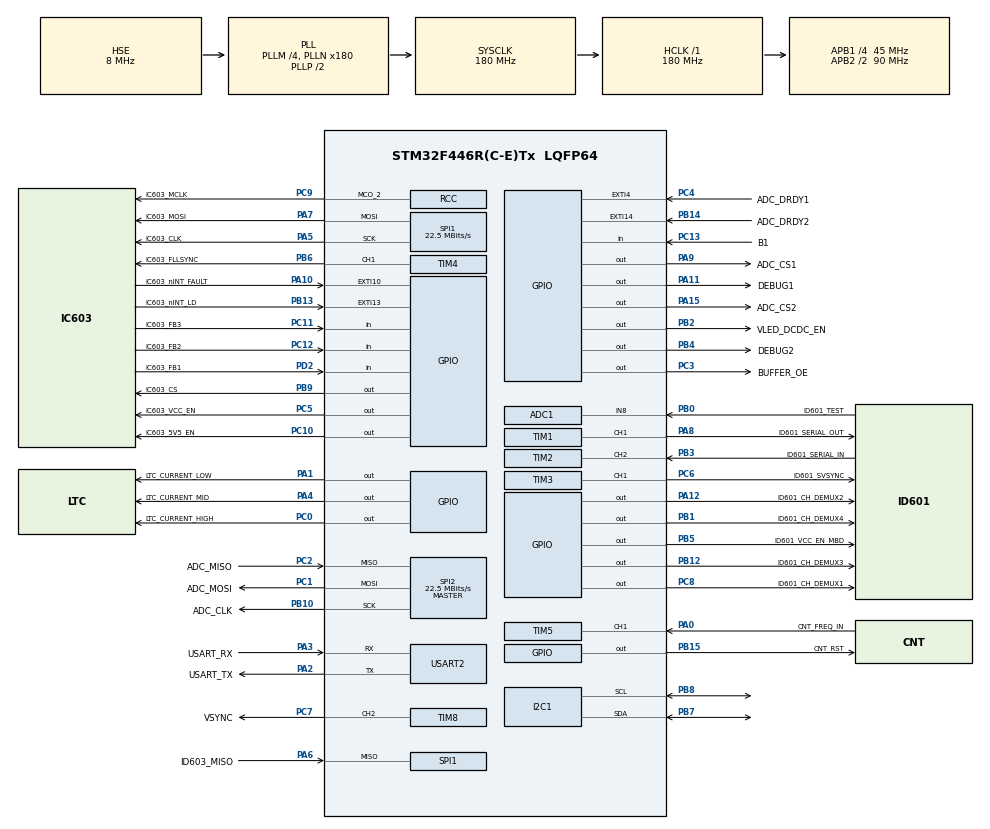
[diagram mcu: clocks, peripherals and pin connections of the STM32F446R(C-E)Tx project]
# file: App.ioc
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ADC1.Channel-0\#ChannelRegularConversion=ADC_CHANNEL_8
ADC1.ContinuousConvMode=ENABLE
ADC1.NbrOfConversionFlag=1
ADC1.Rank-0\#ChannelRegularConversion=1
ADC1.SamplingTime-0\#ChannelRegularConversion=ADC_SAMPLETIME_480CYCLES
ADC1.master=1
Dma.Request0=TIM1_CH1
Dma.Request1=TIM2_CH2/CH4
Dma.Request2=TIM5_CH1
Dma.Request3=SPI1_TX
Dma.Request4=SPI2_TX
Dma.Request5=SPI1_RX
Dma.Request6=SPI2_RX
Dma.SPI1_RX.5.Direction=DMA_PERIPH_TO_MEMORY
Dma.SPI1_RX.5.FIFOMode=DMA_FIFOMODE_DISABLE
Dma.SPI1_RX.5.Instance=DMA2_Stream0
Dma.SPI1_RX.5.MemDataAlignment=DMA_MDATAALIGN_HALFWORD
Dma.SPI1_RX.5.MemInc=DMA_MINC_ENABLE
Dma.SPI1_RX.5.Mode=DMA_NORMAL
Dma.SPI1_RX.5.PeriphDataAlignment=DMA_PDATAALIGN_HALFWORD
Dma.SPI1_RX.5.PeriphInc=DMA_PINC_DISABLE
Dma.SPI1_RX.5.Priority=DMA_PRIORITY_LOW
Dma.SPI1_TX.3.Direction=DMA_MEMORY_TO_PERIPH
Dma.SPI1_TX.3.FIFOMode=DMA_FIFOMODE_DISABLE
Dma.SPI1_TX.3.Instance=DMA2_Stream3
Dma.SPI1_TX.3.MemDataAlignment=DMA_MDATAALIGN_HALFWORD
Dma.SPI1_TX.3.MemInc=DMA_MINC_ENABLE
Dma.SPI1_TX.3.Mode=DMA_NORMAL
Dma.SPI1_TX.3.PeriphDataAlignment=DMA_PDATAALIGN_HALFWORD
Dma.SPI1_TX.3.PeriphInc=DMA_PINC_DISABLE
Dma.SPI1_TX.3.Priority=DMA_PRIORITY_LOW
Dma.SPI2_RX.6.Direction=DMA_PERIPH_TO_MEMORY
Dma.SPI2_RX.6.FIFOMode=DMA_FIFOMODE_DISABLE
Dma.SPI2_RX.6.Instance=DMA1_Stream3
Dma.SPI2_RX.6.MemDataAlignment=DMA_MDATAALIGN_BYTE
Dma.SPI2_RX.6.MemInc=DMA_MINC_ENABLE
Dma.SPI2_RX.6.Mode=DMA_NORMAL
Dma.SPI2_RX.6.PeriphDataAlignment=DMA_PDATAALIGN_BYTE
Dma.SPI2_RX.6.PeriphInc=DMA_PINC_DISABLE
Dma.SPI2_RX.6.Priority=DMA_PRIORITY_LOW
Dma.SPI2_TX.4.Direction=DMA_MEMORY_TO_PERIPH
Dma.SPI2_TX.4.FIFOMode=DMA_FIFOMODE_DISABLE
Dma.SPI2_TX.4.Instance=DMA1_Stream4
Dma.SPI2_TX.4.MemDataAlignment=DMA_MDATAALIGN_BYTE
Dma.SPI2_TX.4.MemInc=DMA_MINC_ENABLE
Dma.SPI2_TX.4.Mode=DMA_NORMAL
Dma.SPI2_TX.4.PeriphDataAlignment=DMA_PDATAALIGN_BYTE
Dma.SPI2_TX.4.PeriphInc=DMA_PINC_DISABLE
Dma.SPI2_TX.4.Priority=DMA_PRIORITY_LOW
Dma.TIM1_CH1.0.Direction=DMA_MEMORY_TO_PERIPH
Dma.TIM1_CH1.0.FIFOMode=DMA_FIFOMODE_DISABLE
Dma.TIM1_CH1.0.Instance=DMA2_Stream1
Dma.TIM1_CH1.0.MemDataAlignment=DMA_MDATAALIGN_HALFWORD
Dma.TIM1_CH1.0.MemInc=DMA_MINC_ENABLE
Dma.TIM1_CH1.0.Mode=DMA_NORMAL
Dma.TIM1_CH1.0.PeriphDataAlignment=DMA_PDATAALIGN_HALFWORD
Dma.TIM1_CH1.0.PeriphInc=DMA_PINC_DISABLE
Dma.TIM1_CH1.0.Priority=DMA_PRIORITY_LOW
Dma.TIM2_CH2/CH4.1.Direction=DMA_PERIPH_TO_MEMORY
Dma.TIM2_CH2/CH4.1.FIFOMode=DMA_FIFOMODE_DISABLE
Dma.TIM2_CH2/CH4.1.Instance=DMA1_Stream6
Dma.TIM2_CH2/CH4.1.MemDataAlignment=DMA_MDATAALIGN_HALFWORD
Dma.TIM2_CH2/CH4.1.MemInc=DMA_MINC_ENABLE
Dma.TIM2_CH2/CH4.1.Mode=DMA_NORMAL
Dma.TIM2_CH2/CH4.1.PeriphDataAlignment=DMA_PDATAALIGN_HALFWORD
Dma.TIM2_CH2/CH4.1.PeriphInc=DMA_PINC_DISABLE
Dma.TIM2_CH2/CH4.1.Priority=DMA_PRIORITY_LOW
Dma.TIM5_CH1.2.Direction=DMA_PERIPH_TO_MEMORY
Dma.TIM5_CH1.2.FIFOMode=DMA_FIFOMODE_DISABLE
Dma.TIM5_CH1.2.Instance=DMA1_Stream2
Dma.TIM5_CH1.2.MemDataAlignment=DMA_MDATAALIGN_WORD
Dma.TIM5_CH1.2.MemInc=DMA_MINC_ENABLE
Dma.TIM5_CH1.2.Mode=DMA_NORMAL
Dma.TIM5_CH1.2.PeriphDataAlignment=DMA_PDATAALIGN_WORD
Dma.TIM5_CH1.2.PeriphInc=DMA_PINC_DISABLE
Dma.TIM5_CH1.2.Priority=DMA_PRIORITY_LOW
FREERTOS.Tasks01=ID601TestTask,24,1024,StartID601TestTask,Default,NULL,Dynamic,NULL,NULL;CLITask,8,1024,StartCLITask,Default,NULL,Dynamic,NULL,NULL;ID601TrimTask,8,1024,StartID601TrimTask,Default,NULL,Dynamic,NULL,NULL;VsyncTask,8,256,StartVsyncTask,Default,NULL,Dynamic,NULL,NULL;BTNTask,8,128,StartBTNTask,Default,NULL,Dynamic,NULL,NULL
Mcu.Family=STM32F4
Mcu.Name=STM32F446R(C-E)Tx
Mcu.Package=LQFP64
NVIC.ADC_IRQn=true\:5\:0\:false\:false\:true\:true\:true\:true\:true
NVIC.DMA1_Stream2_IRQn=true\:5\:0\:false\:false\:true\:true\:false\:true\:true
NVIC.DMA1_Stream3_IRQn=true\:5\:0\:false\:false\:true\:true\:false\:true\:true
NVIC.DMA1_Stream4_IRQn=true\:5\:0\:false\:false\:true\:true\:false\:true\:true
NVIC.DMA1_Stream6_IRQn=true\:5\:0\:false\:false\:true\:true\:false\:true\:true
NVIC.DMA2_Stream0_IRQn=true\:5\:0\:false\:false\:true\:true\:false\:true\:true
NVIC.DMA2_Stream1_IRQn=true\:5\:0\:false\:false\:true\:true\:false\:true\:true
NVIC.DMA2_Stream3_IRQn=true\:5\:0\:false\:false\:true\:true\:false\:true\:true
NVIC.EXTI15_10_IRQn=true\:5\:0\:false\:false\:true\:true\:true\:true\:true
NVIC.EXTI4_IRQn=true\:5\:0\:false\:false\:true\:true\:true\:true\:true
NVIC.PriorityGroup=NVIC_PRIORITYGROUP_4
NVIC.TIM1_TRG_COM_TIM11_IRQn=true\:6\:0\:true\:false\:true\:true\:true\:true\:true
NVIC.TIM3_IRQn=true\:5\:0\:false\:false\:true\:true\:true\:true\:true
NVIC.TIM8_BRK_TIM12_IRQn=true\:5\:0\:false\:false\:true\:true\:true\:true\:true
NVIC.TIM8_TRG_COM_TIM14_IRQn=true\:4\:0\:true\:false\:true\:false\:false\:true\:true
NVIC.TIM8_UP_TIM13_IRQn=true\:6\:0\:true\:false\:true\:true\:true\:true\:true
NVIC.TimeBase=TIM8_TRG_COM_TIM14_IRQn
NVIC.TimeBaseIP=TIM14
NVIC.USART2_IRQn=true\:5\:0\:false\:false\:true\:true\:true\:true\:true
PA0-WKUP.GPIO_Label=CNT_FREQ_IN
PA0-WKUP.GPIO_Speed=GPIO_SPEED_FREQ_VERY_HIGH
PA0-WKUP.Signal=S_TIM5_CH1
PA1.GPIO_Label=LTC_CURRENT_LOW
PA1.Signal=GPIO_Output
PA10.GPIO_Label=IC603_nINT_FAULT
PA10.GPIO_ModeDefaultEXTI=GPIO_MODE_IT_FALLING
PA10.GPIO_PuPd=GPIO_NOPULL
PA10.Signal=GPXTI10
PA11.GPIO_Label=DEBUG1
PA11.Signal=GPIO_Output
PA12.GPIO_Label=ID601_CH_DEMUX2
PA12.PinState=GPIO_PIN_SET
PA12.Signal=GPIO_Output
PA13.GPIO_Label=TMS
PA13.Mode=Serial_Wire
PA13.Signal=SYS_JTMS-SWDIO
PA14.GPIO_Label=TCK
PA14.Mode=Serial_Wire
PA14.Signal=SYS_JTCK-SWCLK
PA15.GPIO_Label=ADC_CS2
PA15.GPIO_Speed=GPIO_SPEED_FREQ_LOW
PA15.PinState=GPIO_PIN_SET
PA15.Signal=GPIO_Output
PA2.GPIO_Label=USART_TX
PA2.Mode=Asynchronous
PA2.Signal=USART2_TX
PA3.GPIO_Label=USART_RX
PA3.Mode=Asynchronous
PA3.Signal=USART2_RX
PA4.GPIO_Label=LTC_CURRENT_MID
PA4.Signal=GPIO_Output
PA5.GPIO_Label=IC603_CLK
PA5.Mode=Full_Duplex_Master
PA5.Signal=SPI1_SCK
PA6.GPIO_Label=ID603_MISO
PA6.Mode=Full_Duplex_Master
PA6.Signal=SPI1_MISO
PA7.GPIO_Label=IC603_MOSI
PA7.Mode=Full_Duplex_Master
PA7.Signal=SPI1_MOSI
PA8.GPIO_Label=ID601_SERIAL_OUT
PA8.GPIO_Speed=GPIO_SPEED_FREQ_HIGH
PA8.Signal=S_TIM1_CH1
PA9.GPIO_Label=ADC_CS1
PA9.GPIO_Speed=GPIO_SPEED_FREQ_LOW
PA9.PinState=GPIO_PIN_SET
PA9.Signal=GPIO_Output
PB0.GPIO_Label=ID601_TEST
PB0.Signal=ADCx_IN8
PB1.GPIO_Label=ID601_CH_DEMUX4
PB1.PinState=GPIO_PIN_SET
PB1.Signal=GPIO_Output
PB10.GPIO_Label=ADC_CLK
PB10.Mode=Full_Duplex_Master
PB10.Signal=SPI2_SCK
PB12.GPIO_Label=ID601_CH_DEMUX3
PB12.PinState=GPIO_PIN_SET
PB12.Signal=GPIO_Output
PB13.GPIO_Label=IC603_nINT_LD
PB13.GPIO_ModeDefaultEXTI=GPIO_MODE_IT_FALLING
PB13.GPIO_PuPd=GPIO_NOPULL
PB13.Signal=GPXTI13
PB14.GPIO_Label=ADC_DRDY2
PB14.GPIO_ModeDefaultEXTI=GPIO_MODE_IT_FALLING
PB14.GPIO_PuPd=GPIO_PULLUP
PB14.Signal=GPXTI14
PB15.GPIO_Label=CNT_RST
PB15.GPIO_Speed=GPIO_SPEED_FREQ_LOW
PB15.PinState=GPIO_PIN_SET
PB15.Signal=GPIO_Output
PB2.GPIO_Label=VLED_DCDC_EN
PB2.PinState=GPIO_PIN_SET
PB2.Signal=GPIO_Output
PB3.GPIO_Label=ID601_SERIAL_IN
PB3.GPIO_Speed=GPIO_SPEED_FREQ_VERY_HIGH
PB3.Signal=S_TIM2_CH2
PB4.GPIO_Label=DEBUG2
PB4.Signal=GPIO_Output
PB5.GPIO_Label=ID601_VCC_EN_MBD
PB5.PinState=GPIO_PIN_SET
PB5.Signal=GPIO_Output
PB6.GPIO_Label=IC603_FLLSYNC
PB6.GPIO_Speed=GPIO_SPEED_FREQ_HIGH
PB6.Signal=S_TIM4_CH1
PB7.Mode=I2C
PB7.Signal=I2C1_SDA
PB8.Mode=I2C
PB8.Signal=I2C1_SCL
PB9.GPIO_Label=IC603_CS
PB9.PinState=GPIO_PIN_SET
PB9.Signal=GPIO_Output
PC0.GPIO_Label=LTC_CURRENT_HIGH
PC0.Signal=GPIO_Output
PC1.GPIO_Label=ADC_MOSI
PC1.Mode=Full_Duplex_Master
PC1.Signal=SPI2_MOSI
PC10.GPIO_Label=IC603_5V5_EN
PC10.Signal=GPIO_Output
PC11.GPIO_Label=IC603_FB3
PC11.Signal=GPIO_Input
PC12.GPIO_Label=IC603_FB2
PC12.Signal=GPIO_Input
PC13.GPIO_Label=B1
PC13.Signal=GPIO_Input
PC14-OSC32_IN.Mode=LSE-External-Oscillator
PC14-OSC32_IN.Signal=RCC_OSC32_IN
PC15-OSC32_OUT.Mode=LSE-External-Oscillator
PC15-OSC32_OUT.Signal=RCC_OSC32_OUT
PC2.GPIO_Label=ADC_MISO
PC2.Mode=Full_Duplex_Master
PC2.Signal=SPI2_MISO
PC3.GPIO_Label=BUFFER_OE
PC3.GPIO_Speed=GPIO_SPEED_FREQ_LOW
PC3.Signal=GPIO_Output
PC4.GPIO_Label=ADC_DRDY1
PC4.GPIO_ModeDefaultEXTI=GPIO_MODE_IT_FALLING
PC4.GPIO_PuPd=GPIO_PULLUP
PC4.Signal=GPXTI4
PC5.GPIO_Label=IC603_VCC_EN
PC5.PinState=GPIO_PIN_SET
PC5.Signal=GPIO_Output
PC6.GPIO_Label=ID601_SVSYNC
PC6.GPIO_Speed=GPIO_SPEED_FREQ_HIGH
PC6.Signal=S_TIM3_CH1
PC7.GPIO_Label=VSYNC
PC7.Signal=S_TIM8_CH2
PC8.GPIO_Label=ID601_CH_DEMUX1
PC8.PinState=GPIO_PIN_SET
PC8.Signal=GPIO_Output
PC9.GPIO_Label=IC603_MCLK
PC9.Mode=Clock-out-2
PC9.Signal=RCC_MCO_2
PD2.GPIO_Label=IC603_FB1
PD2.Signal=GPIO_Input
PH0-OSC_IN.Mode=HSE-External-Oscillator
PH0-OSC_IN.Signal=RCC_OSC_IN
PH1-OSC_OUT.Mode=HSE-External-Oscillator
PH1-OSC_OUT.Signal=RCC_OSC_OUT
ProjectManager.HeapSize=0x200
ProjectManager.StackSize=0x400
ProjectManager.TargetToolchain=EWARM V8.50
RCC.AHBFreq_Value=180000000
RCC.APB1CLKDivider=RCC_HCLK_DIV4
RCC.APB1Freq_Value=45000000
RCC.APB1TimFreq_Value=90000000
RCC.APB2CLKDivider=RCC_HCLK_DIV2
RCC.APB2Freq_Value=90000000
RCC.APB2TimFreq_Value=180000000
RCC.CortexFreq_Value=180000000
RCC.FLatency-AdvancedSettings=FLASH_LATENCY_5
RCC.HCLKFreq_Value=180000000
RCC.HSE_VALUE=8000000
RCC.HSI_VALUE=16000000
RCC.PLLM=4
RCC.PLLN=180
RCC.PLLSourceVirtual=RCC_PLLSOURCE_HSE
RCC.RCC_MCODiv2=RCC_MCODIV_2
RCC.SYSCLKFreq_VALUE=180000000
RCC.SYSCLKSource=RCC_SYSCLKSOURCE_PLLCLK
RCC.USBFreq_Value=180000000
RCC.VCOOutputFreq_Value=360000000
SH.ADCx_IN8.0=ADC1_IN8,IN8
SH.S_TIM1_CH1.0=TIM1_CH1,PWM Generation1 CH1
SH.S_TIM2_CH2.0=TIM2_CH2,PWM_Input_2
SH.S_TIM3_CH1.0=TIM3_CH1,PWM Generation1 CH1
SH.S_TIM4_CH1.0=TIM4_CH1,PWM Generation1 CH1
SH.S_TIM5_CH1.0=TIM5_CH1,Input_Capture1_from_TI1
SH.S_TIM8_CH2.0=TIM8_CH2,PWM Generation2 CH2
SPI1.BaudRatePrescaler=SPI_BAUDRATEPRESCALER_4
SPI1.CLKPhase=SPI_PHASE_2EDGE
SPI1.CalculateBaudRate=22.5 MBits/s
SPI1.DataSize=SPI_DATASIZE_16BIT
SPI1.Direction=SPI_DIRECTION_2LINES
SPI1.Mode=SPI_MODE_MASTER
SPI1.VirtualType=VM_MASTER
SPI2.CLKPhase=SPI_PHASE_2EDGE
SPI2.CalculateBaudRate=22.5 MBits/s
SPI2.Direction=SPI_DIRECTION_2LINES
SPI2.Mode=SPI_MODE_MASTER
SPI2.VirtualType=VM_MASTER
TIM1.AutomaticOutput=TIM_AUTOMATICOUTPUT_ENABLE
TIM1.Channel-PWM\ Generation1\ CH1=TIM_CHANNEL_1
TIM1.Period=179
TIM11.Period=59999
TIM11.Prescaler=24
TIM13.Prescaler=89
TIM2.ICPolarity_1=TIM_INPUTCHANNELPOLARITY_FALLING
TIM3.Channel-PWM\ Generation1\ CH1=TIM_CHANNEL_1
TIM3.OC1Preload_PWM=DISABLE
TIM3.Prescaler=1
TIM4.Channel-PWM\ Generation1\ CH1=TIM_CHANNEL_1
TIM4.Period=49999
TIM4.Prescaler=8
TIM5.Channel-Input_Capture1_from_TI1=TIM_CHANNEL_1
TIM8.AutoReloadPreload=TIM_AUTORELOAD_PRELOAD_ENABLE
TIM8.AutomaticOutput=TIM_AUTOMATICOUTPUT_ENABLE
TIM8.Channel-PWM\ Generation2\ CH2=TIM_CHANNEL_2
TIM8.Period=59999
TIM8.Prescaler=49
TIM8.TIM_MasterSlaveMode=TIM_MASTERSLAVEMODE_ENABLE
USART2.VirtualMode=VM_ASYNC
VP_FREERTOS_VS_CMSIS_V2.Mode=CMSIS_V2
VP_SYS_VS_tim14.Mode=TIM14
VP_TIM11_VS_ClockSourceINT.Mode=Enable_Timer
VP_TIM13_VS_ClockSourceINT.Mode=Enable_Timer
VP_TIM1_VS_ClockSourceINT.Mode=Internal
VP_TIM2_VS_ClockSourceINT.Mode=Internal
VP_TIM3_VS_ClockSourceINT.Mode=Internal
VP_TIM4_VS_ClockSourceINT.Mode=Internal
VP_TIM5_VS_ClockSourceINT.Mode=Internal
VP_TIM8_VS_ClockSourceINT.Mode=Internal
board=NUCLEO-F446RE

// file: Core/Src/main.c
/* USER CODE BEGIN Header */
/**
  ******************************************************************************
  * @file           : main.c
  * @brief          : Main program body
  ******************************************************************************
  * @attention
  *
  * Copyright (c) 2026 STMicroelectronics.
  * All rights reserved.
  *
  * This software is licensed under terms that can be found in the LICENSE file
  * in the root directory of this software component.
  * If no LICENSE file comes with this software, it is provided AS-IS.
  *
  ******************************************************************************
  */
/* USER CODE END Header */
#include "main.h"
#include "cmsis_os.h"

/* USER CODE BEGIN Includes */
#include "cli.h"
#include "drv_gpio.h"
#include "drv_uart.h"
#include "drv_timer.h"
#include "drv_id601.h"
#include "id601_trim.h"
#include "id601_test.h"
#include "id601_dimming.h"
#include "drv_ads114s08.h"
#include "common_def.h"
/* USER CODE END Includes */

I2C_HandleTypeDef hi2c1;

/* Definitions for ID601TestTask */
osThreadId_t ID601TestTaskHandle;
const osThreadAttr_t ID601TestTask_attributes = {
  .name = "ID601TestTask",
  .stack_size = 1024 * 4,
  .priority = (osPriority_t) osPriorityNormal,
};
/* Definitions for CLITask */
osThreadId_t CLITaskHandle;
const osThreadAttr_t CLITask_attributes = {
  .name = "CLITask",
  .stack_size = 1024 * 4,
  .priority = (osPriority_t) osPriorityLow,
};
/* Definitions for ID601TrimTask */
osThreadId_t ID601TrimTaskHandle;
const osThreadAttr_t ID601TrimTask_attributes = {
  .name = "ID601TrimTask",
  .stack_size = 1024 * 4,
  .priority = (osPriority_t) osPriorityLow,
};
/* Definitions for VsyncTask */
osThreadId_t VsyncTaskHandle;
const osThreadAttr_t VsyncTask_attributes = {
  .name = "VsyncTask",
  .stack_size = 256 * 4,
  .priority = (osPriority_t) osPriorityLow,
};
/* Definitions for BTNTask */
osThreadId_t BTNTaskHandle;
const osThreadAttr_t BTNTask_attributes = {
  .name = "BTNTask",
  .stack_size = 128 * 4,
  .priority = (osPriority_t) osPriorityLow,
};

void SystemClock_Config(void);
static void MX_GPIO_Init(void);
static void MX_DMA_Init(void);
static void MX_SPI1_Init(void);
static void MX_USART2_UART_Init(void);
static void MX_ADC1_Init(void);
static void MX_SPI2_Init(void);
static void MX_TIM1_Init(void);
static void MX_TIM2_Init(void);
static void MX_TIM3_Init(void);
static void MX_TIM4_Init(void);
static void MX_TIM5_Init(void);
static void MX_TIM8_Init(void);
static void MX_TIM13_Init(void);
static void MX_I2C1_Init(void);
static void MX_TIM11_Init(void);
void StartID601TestTask(void *argument);
void StartCLITask(void *argument);
void StartID601TrimTask(void *argument);
void StartVsyncTask(void *argument);
void StartBTNTask(void *argument);

int main(void)
{

  /* USER CODE BEGIN 1 */
  __enable_irq();
  /* USER CODE END 1 */

  /* MCU Configuration--------------------------------------------------------*/

  /* Reset of all peripherals, Initializes the Flash interface and the Systick. */
  HAL_Init();

  /* Configure the system clock */
  SystemClock_Config();

  /* Initialize all configured peripherals */
  MX_GPIO_Init();
  MX_DMA_Init();
  MX_SPI1_Init();
  MX_USART2_UART_Init();
  MX_ADC1_Init();
  MX_SPI2_Init();
  MX_TIM1_Init();
  MX_TIM2_Init();
  MX_TIM3_Init();
  MX_TIM4_Init();
  MX_TIM5_Init();
  MX_TIM8_Init();
  MX_TIM13_Init();
  MX_I2C1_Init();
  MX_TIM11_Init();
  /* USER CODE BEGIN 2 */
    drv_uart_init();

    drv_tim_init();
    drv_gpio_init();
    drv_id601_init();
    ads114s08_init();

    cli_init();
  /* USER CODE END 2 */

  /* Init scheduler */
  osKernelInitialize();

  /* USER CODE BEGIN RTOS_MUTEX */
  /* add mutexes, ... */
    drv_id601_make_mutex();
    drv_uart_make_mutex();
  /* USER CODE END RTOS_MUTEX */

  /* Create the thread(s) */
  /* creation of ID601TestTask */
  ID601TestTaskHandle = osThreadNew(StartID601TestTask, NULL, &ID601TestTask_attributes);

  /* creation of CLITask */
  CLITaskHandle = osThreadNew(StartCLITask, NULL, &CLITask_attributes);

  /* creation of ID601TrimTask */
  ID601TrimTaskHandle = osThreadNew(StartID601TrimTask, NULL, &ID601TrimTask_attributes);

  /* creation of VsyncTask */
  VsyncTaskHandle = osThreadNew(StartVsyncTask, NULL, &VsyncTask_attributes);

  /* creation of BTNTask */
  BTNTaskHandle = osThreadNew(StartBTNTask, NULL, &BTNTask_attributes);

  /* Start scheduler */
  osKernelStart();

  /* We should never get here as control is now taken by the scheduler */

  /* Infinite loop */
  while (1)
  {

  }
}

void SystemClock_Config(void)
{
  RCC_OscInitTypeDef RCC_OscInitStruct = {0};
  RCC_ClkInitTypeDef RCC_ClkInitStruct = {0};

  /** Configure the main internal regulator output voltage
  */
  __HAL_RCC_PWR_CLK_ENABLE();
  __HAL_PWR_VOLTAGESCALING_CONFIG(PWR_REGULATOR_VOLTAGE_SCALE1);

  /** Initializes the RCC Oscillators according to the specified parameters
  * in the RCC_OscInitTypeDef structure.
  */
  RCC_OscInitStruct.OscillatorType = RCC_OSCILLATORTYPE_HSE;
  RCC_OscInitStruct.HSEState = RCC_HSE_ON;
  RCC_OscInitStruct.PLL.PLLState = RCC_PLL_ON;
  RCC_OscInitStruct.PLL.PLLSource = RCC_PLLSOURCE_HSE;
  RCC_OscInitStruct.PLL.PLLM = 4;
  RCC_OscInitStruct.PLL.PLLN = 180;
  RCC_OscInitStruct.PLL.PLLP = RCC_PLLP_DIV2;
  RCC_OscInitStruct.PLL.PLLQ = 2;
  RCC_OscInitStruct.PLL.PLLR = 2;
  if (HAL_RCC_OscConfig(&RCC_OscInitStruct) != HAL_OK)
  {
    Error_Handler();
  }

  /** Activate the Over-Drive mode
  */
  if (HAL_PWREx_EnableOverDrive() != HAL_OK)
  {
    Error_Handler();
  }

  /** Initializes the CPU, AHB and APB buses clocks
  */
  RCC_ClkInitStruct.ClockType = RCC_CLOCKTYPE_HCLK|RCC_CLOCKTYPE_SYSCLK
                              |RCC_CLOCKTYPE_PCLK1|RCC_CLOCKTYPE_PCLK2;
  RCC_ClkInitStruct.SYSCLKSource = RCC_SYSCLKSOURCE_PLLCLK;
  RCC_ClkInitStruct.AHBCLKDivider = RCC_SYSCLK_DIV1;
  RCC_ClkInitStruct.APB1CLKDivider = RCC_HCLK_DIV4;
  RCC_ClkInitStruct.APB2CLKDivider = RCC_HCLK_DIV2;

  if (HAL_RCC_ClockConfig(&RCC_ClkInitStruct, FLASH_LATENCY_5) != HAL_OK)
  {
    Error_Handler();
  }
  HAL_RCC_MCOConfig(RCC_MCO2, RCC_MCO2SOURCE_SYSCLK, RCC_MCODIV_2);
}

static void MX_ADC1_Init(void)
{

  LL_ADC_InitTypeDef ADC_InitStruct = {0};
  LL_ADC_REG_InitTypeDef ADC_REG_InitStruct = {0};
  LL_ADC_CommonInitTypeDef ADC_CommonInitStruct = {0};

  LL_GPIO_InitTypeDef GPIO_InitStruct = {0};

  /* Peripheral clock enable */
  LL_APB2_GRP1_EnableClock(LL_APB2_GRP1_PERIPH_ADC1);

  LL_AHB1_GRP1_EnableClock(LL_AHB1_GRP1_PERIPH_GPIOB);
  /**ADC1 GPIO Configuration
  PB0   ------> ADC1_IN8
  */
  GPIO_InitStruct.Pin = ID601_TEST_Pin;
  GPIO_InitStruct.Mode = LL_GPIO_MODE_ANALOG;
  GPIO_InitStruct.Pull = LL_GPIO_PULL_NO;
  LL_GPIO_Init(ID601_TEST_GPIO_Port, &GPIO_InitStruct);

  /* ADC1 interrupt Init */
  NVIC_SetPriority(ADC_IRQn, NVIC_EncodePriority(NVIC_GetPriorityGrouping(),5, 0));
  NVIC_EnableIRQ(ADC_IRQn);

  /** Common config
  */
  ADC_InitStruct.Resolution = LL_ADC_RESOLUTION_12B;
  ADC_InitStruct.DataAlignment = LL_ADC_DATA_ALIGN_RIGHT;
  ADC_InitStruct.SequencersScanMode = LL_ADC_SEQ_SCAN_DISABLE;
  LL_ADC_Init(ADC1, &ADC_InitStruct);
  ADC_REG_InitStruct.TriggerSource = LL_ADC_REG_TRIG_SOFTWARE;
  ADC_REG_InitStruct.SequencerLength = LL_ADC_REG_SEQ_SCAN_DISABLE;
  ADC_REG_InitStruct.SequencerDiscont = LL_ADC_REG_SEQ_DISCONT_DISABLE;
  ADC_REG_InitStruct.ContinuousMode = LL_ADC_REG_CONV_CONTINUOUS;
  ADC_REG_InitStruct.DMATransfer = LL_ADC_REG_DMA_TRANSFER_NONE;
  LL_ADC_REG_Init(ADC1, &ADC_REG_InitStruct);
  LL_ADC_REG_SetFlagEndOfConversion(ADC1, LL_ADC_REG_FLAG_EOC_UNITARY_CONV);
  ADC_CommonInitStruct.CommonClock = LL_ADC_CLOCK_SYNC_PCLK_DIV4;
  ADC_CommonInitStruct.Multimode = LL_ADC_MULTI_INDEPENDENT;
  LL_ADC_CommonInit(__LL_ADC_COMMON_INSTANCE(ADC1), &ADC_CommonInitStruct);

  /** Configure Regular Channel
  */
  LL_ADC_REG_SetSequencerRanks(ADC1, LL_ADC_REG_RANK_1, LL_ADC_CHANNEL_8);
  LL_ADC_SetChannelSamplingTime(ADC1, LL_ADC_CHANNEL_8, LL_ADC_SAMPLINGTIME_480CYCLES);

}

static void MX_I2C1_Init(void)
{

  hi2c1.Instance = I2C1;
  hi2c1.Init.ClockSpeed = 100000;
  hi2c1.Init.DutyCycle = I2C_DUTYCYCLE_2;
  hi2c1.Init.OwnAddress1 = 0;
  hi2c1.Init.AddressingMode = I2C_ADDRESSINGMODE_7BIT;
  hi2c1.Init.DualAddressMode = I2C_DUALADDRESS_DISABLE;
  hi2c1.Init.OwnAddress2 = 0;
  hi2c1.Init.GeneralCallMode = I2C_GENERALCALL_DISABLE;
  hi2c1.Init.NoStretchMode = I2C_NOSTRETCH_DISABLE;
  if (HAL_I2C_Init(&hi2c1) != HAL_OK)
  {
    Error_Handler();
  }

}

static void MX_SPI1_Init(void)
{

  LL_SPI_InitTypeDef SPI_InitStruct = {0};

  LL_GPIO_InitTypeDef GPIO_InitStruct = {0};

  /* Peripheral clock enable */
  LL_APB2_GRP1_EnableClock(LL_APB2_GRP1_PERIPH_SPI1);

  LL_AHB1_GRP1_EnableClock(LL_AHB1_GRP1_PERIPH_GPIOA);
  /**SPI1 GPIO Configuration
  PA5   ------> SPI1_SCK
  PA6   ------> SPI1_MISO
  PA7   ------> SPI1_MOSI
  */
  GPIO_InitStruct.Pin = IC603_CLK_Pin|ID603_MISO_Pin|IC603_MOSI_Pin;
  GPIO_InitStruct.Mode = LL_GPIO_MODE_ALTERNATE;
  GPIO_InitStruct.Speed = LL_GPIO_SPEED_FREQ_VERY_HIGH;
  GPIO_InitStruct.OutputType = LL_GPIO_OUTPUT_PUSHPULL;
  GPIO_InitStruct.Pull = LL_GPIO_PULL_NO;
  GPIO_InitStruct.Alternate = LL_GPIO_AF_5;
  LL_GPIO_Init(GPIOA, &GPIO_InitStruct);

  /* SPI1 DMA Init */

  /* SPI1_TX Init */
  LL_DMA_SetChannelSelection(DMA2, LL_DMA_STREAM_3, LL_DMA_CHANNEL_3);

  LL_DMA_SetDataTransferDirection(DMA2, LL_DMA_STREAM_3, LL_DMA_DIRECTION_MEMORY_TO_PERIPH);

  LL_DMA_SetStreamPriorityLevel(DMA2, LL_DMA_STREAM_3, LL_DMA_PRIORITY_LOW);

  LL_DMA_SetMode(DMA2, LL_DMA_STREAM_3, LL_DMA_MODE_NORMAL);

  LL_DMA_SetPeriphIncMode(DMA2, LL_DMA_STREAM_3, LL_DMA_PERIPH_NOINCREMENT);

  LL_DMA_SetMemoryIncMode(DMA2, LL_DMA_STREAM_3, LL_DMA_MEMORY_INCREMENT);

  LL_DMA_SetPeriphSize(DMA2, LL_DMA_STREAM_3, LL_DMA_PDATAALIGN_HALFWORD);

  LL_DMA_SetMemorySize(DMA2, LL_DMA_STREAM_3, LL_DMA_MDATAALIGN_HALFWORD);

  LL_DMA_DisableFifoMode(DMA2, LL_DMA_STREAM_3);

  /* SPI1_RX Init */
  LL_DMA_SetChannelSelection(DMA2, LL_DMA_STREAM_0, LL_DMA_CHANNEL_3);

  LL_DMA_SetDataTransferDirection(DMA2, LL_DMA_STREAM_0, LL_DMA_DIRECTION_PERIPH_TO_MEMORY);

  LL_DMA_SetStreamPriorityLevel(DMA2, LL_DMA_STREAM_0, LL_DMA_PRIORITY_LOW);

  LL_DMA_SetMode(DMA2, LL_DMA_STREAM_0, LL_DMA_MODE_NORMAL);

  LL_DMA_SetPeriphIncMode(DMA2, LL_DMA_STREAM_0, LL_DMA_PERIPH_NOINCREMENT);

  LL_DMA_SetMemoryIncMode(DMA2, LL_DMA_STREAM_0, LL_DMA_MEMORY_INCREMENT);

  LL_DMA_SetPeriphSize(DMA2, LL_DMA_STREAM_0, LL_DMA_PDATAALIGN_HALFWORD);

  LL_DMA_SetMemorySize(DMA2, LL_DMA_STREAM_0, LL_DMA_MDATAALIGN_HALFWORD);

  LL_DMA_DisableFifoMode(DMA2, LL_DMA_STREAM_0);

  /* SPI1 parameter configuration*/
  SPI_InitStruct.TransferDirection = LL_SPI_FULL_DUPLEX;
  SPI_InitStruct.Mode = LL_SPI_MODE_MASTER;
  SPI_InitStruct.DataWidth = LL_SPI_DATAWIDTH_16BIT;
  SPI_InitStruct.ClockPolarity = LL_SPI_POLARITY_LOW;
  SPI_InitStruct.ClockPhase = LL_SPI_PHASE_2EDGE;
  SPI_InitStruct.NSS = LL_SPI_NSS_SOFT;
  SPI_InitStruct.BaudRate = LL_SPI_BAUDRATEPRESCALER_DIV4;
  SPI_InitStruct.BitOrder = LL_SPI_MSB_FIRST;
  SPI_InitStruct.CRCCalculation = LL_SPI_CRCCALCULATION_DISABLE;
  SPI_InitStruct.CRCPoly = 10;
  LL_SPI_Init(SPI1, &SPI_InitStruct);
  LL_SPI_SetStandard(SPI1, LL_SPI_PROTOCOL_MOTOROLA);

}

static void MX_SPI2_Init(void)
{

  LL_SPI_InitTypeDef SPI_InitStruct = {0};

  LL_GPIO_InitTypeDef GPIO_InitStruct = {0};

  /* Peripheral clock enable */
  LL_APB1_GRP1_EnableClock(LL_APB1_GRP1_PERIPH_SPI2);

  LL_AHB1_GRP1_EnableClock(LL_AHB1_GRP1_PERIPH_GPIOC);
  LL_AHB1_GRP1_EnableClock(LL_AHB1_GRP1_PERIPH_GPIOB);
  /**SPI2 GPIO Configuration
  PC1   ------> SPI2_MOSI
  PC2   ------> SPI2_MISO
  PB10   ------> SPI2_SCK
  */
  GPIO_InitStruct.Pin = ADC_MOSI_Pin;
  GPIO_InitStruct.Mode = LL_GPIO_MODE_ALTERNATE;
  GPIO_InitStruct.Speed = LL_GPIO_SPEED_FREQ_VERY_HIGH;
  GPIO_InitStruct.OutputType = LL_GPIO_OUTPUT_PUSHPULL;
  GPIO_InitStruct.Pull = LL_GPIO_PULL_NO;
  GPIO_InitStruct.Alternate = LL_GPIO_AF_7;
  LL_GPIO_Init(ADC_MOSI_GPIO_Port, &GPIO_InitStruct);

  GPIO_InitStruct.Pin = ADC_MISO_Pin;
  GPIO_InitStruct.Mode = LL_GPIO_MODE_ALTERNATE;
  GPIO_InitStruct.Speed = LL_GPIO_SPEED_FREQ_VERY_HIGH;
  GPIO_InitStruct.OutputType = LL_GPIO_OUTPUT_PUSHPULL;
  GPIO_InitStruct.Pull = LL_GPIO_PULL_NO;
  GPIO_InitStruct.Alternate = LL_GPIO_AF_5;
  LL_GPIO_Init(ADC_MISO_GPIO_Port, &GPIO_InitStruct);

  GPIO_InitStruct.Pin = ADC_CLK_Pin;
  GPIO_InitStruct.Mode = LL_GPIO_MODE_ALTERNATE;
  GPIO_InitStruct.Speed = LL_GPIO_SPEED_FREQ_VERY_HIGH;
  GPIO_InitStruct.OutputType = LL_GPIO_OUTPUT_PUSHPULL;
  GPIO_InitStruct.Pull = LL_GPIO_PULL_NO;
  GPIO_InitStruct.Alternate = LL_GPIO_AF_5;
  LL_GPIO_Init(ADC_CLK_GPIO_Port, &GPIO_InitStruct);

  /* SPI2 DMA Init */

  /* SPI2_TX Init */
  LL_DMA_SetChannelSelection(DMA1, LL_DMA_STREAM_4, LL_DMA_CHANNEL_0);

  LL_DMA_SetDataTransferDirection(DMA1, LL_DMA_STREAM_4, LL_DMA_DIRECTION_MEMORY_TO_PERIPH);

  LL_DMA_SetStreamPriorityLevel(DMA1, LL_DMA_STREAM_4, LL_DMA_PRIORITY_LOW);

  LL_DMA_SetMode(DMA1, LL_DMA_STREAM_4, LL_DMA_MODE_NORMAL);

  LL_DMA_SetPeriphIncMode(DMA1, LL_DMA_STREAM_4, LL_DMA_PERIPH_NOINCREMENT);

  LL_DMA_SetMemoryIncMode(DMA1, LL_DMA_STREAM_4, LL_DMA_MEMORY_INCREMENT);

  LL_DMA_SetPeriphSize(DMA1, LL_DMA_STREAM_4, LL_DMA_PDATAALIGN_BYTE);

  LL_DMA_SetMemorySize(DMA1, LL_DMA_STREAM_4, LL_DMA_MDATAALIGN_BYTE);

  LL_DMA_DisableFifoMode(DMA1, LL_DMA_STREAM_4);

  /* SPI2_RX Init */
  LL_DMA_SetChannelSelection(DMA1, LL_DMA_STREAM_3, LL_DMA_CHANNEL_0);

  LL_DMA_SetDataTransferDirection(DMA1, LL_DMA_STREAM_3, LL_DMA_DIRECTION_PERIPH_TO_MEMORY);

  LL_DMA_SetStreamPriorityLevel(DMA1, LL_DMA_STREAM_3, LL_DMA_PRIORITY_LOW);

  LL_DMA_SetMode(DMA1, LL_DMA_STREAM_3, LL_DMA_MODE_NORMAL);

  LL_DMA_SetPeriphIncMode(DMA1, LL_DMA_STREAM_3, LL_DMA_PERIPH_NOINCREMENT);

  LL_DMA_SetMemoryIncMode(DMA1, LL_DMA_STREAM_3, LL_DMA_MEMORY_INCREMENT);

  LL_DMA_SetPeriphSize(DMA1, LL_DMA_STREAM_3, LL_DMA_PDATAALIGN_BYTE);

  LL_DMA_SetMemorySize(DMA1, LL_DMA_STREAM_3, LL_DMA_MDATAALIGN_BYTE);

  LL_DMA_DisableFifoMode(DMA1, LL_DMA_STREAM_3);

  /* SPI2 parameter configuration*/
  SPI_InitStruct.TransferDirection = LL_SPI_FULL_DUPLEX;
  SPI_InitStruct.Mode = LL_SPI_MODE_MASTER;
  SPI_InitStruct.DataWidth = LL_SPI_DATAWIDTH_8BIT;
  SPI_InitStruct.ClockPolarity = LL_SPI_POLARITY_LOW;
  SPI_InitStruct.ClockPhase = LL_SPI_PHASE_2EDGE;
  SPI_InitStruct.NSS = LL_SPI_NSS_SOFT;
  SPI_InitStruct.BaudRate = LL_SPI_BAUDRATEPRESCALER_DIV2;
  SPI_InitStruct.BitOrder = LL_SPI_MSB_FIRST;
  SPI_InitStruct.CRCCalculation = LL_SPI_CRCCALCULATION_DISABLE;
  SPI_InitStruct.CRCPoly = 10;
  LL_SPI_Init(SPI2, &SPI_InitStruct);
  LL_SPI_SetStandard(SPI2, LL_SPI_PROTOCOL_MOTOROLA);

}

static void MX_TIM1_Init(void)
{

  LL_TIM_InitTypeDef TIM_InitStruct = {0};
  LL_TIM_OC_InitTypeDef TIM_OC_InitStruct = {0};
  LL_TIM_BDTR_InitTypeDef TIM_BDTRInitStruct = {0};

  LL_GPIO_InitTypeDef GPIO_InitStruct = {0};

  /* Peripheral clock enable */
  LL_APB2_GRP1_EnableClock(LL_APB2_GRP1_PERIPH_TIM1);

  /* TIM1 DMA Init */

  /* TIM1_CH1 Init */
  LL_DMA_SetChannelSelection(DMA2, LL_DMA_STREAM_1, LL_DMA_CHANNEL_6);

  LL_DMA_SetDataTransferDirection(DMA2, LL_DMA_STREAM_1, LL_DMA_DIRECTION_MEMORY_TO_PERIPH);

  LL_DMA_SetStreamPriorityLevel(DMA2, LL_DMA_STREAM_1, LL_DMA_PRIORITY_LOW);

  LL_DMA_SetMode(DMA2, LL_DMA_STREAM_1, LL_DMA_MODE_NORMAL);

  LL_DMA_SetPeriphIncMode(DMA2, LL_DMA_STREAM_1, LL_DMA_PERIPH_NOINCREMENT);

  LL_DMA_SetMemoryIncMode(DMA2, LL_DMA_STREAM_1, LL_DMA_MEMORY_INCREMENT);

  LL_DMA_SetPeriphSize(DMA2, LL_DMA_STREAM_1, LL_DMA_PDATAALIGN_HALFWORD);

  LL_DMA_SetMemorySize(DMA2, LL_DMA_STREAM_1, LL_DMA_MDATAALIGN_HALFWORD);

  LL_DMA_DisableFifoMode(DMA2, LL_DMA_STREAM_1);

  /* TIM1 interrupt Init */
  NVIC_SetPriority(TIM1_TRG_COM_TIM11_IRQn, NVIC_EncodePriority(NVIC_GetPriorityGrouping(),6, 0));
  NVIC_EnableIRQ(TIM1_TRG_COM_TIM11_IRQn);

  TIM_InitStruct.Prescaler = 0;
  TIM_InitStruct.CounterMode = LL_TIM_COUNTERMODE_UP;
  TIM_InitStruct.Autoreload = 179;
  TIM_InitStruct.ClockDivision = LL_TIM_CLOCKDIVISION_DIV1;
  TIM_InitStruct.RepetitionCounter = 0;
  LL_TIM_Init(TIM1, &TIM_InitStruct);
  LL_TIM_DisableARRPreload(TIM1);
  LL_TIM_SetClockSource(TIM1, LL_TIM_CLOCKSOURCE_INTERNAL);
  LL_TIM_OC_EnablePreload(TIM1, LL_TIM_CHANNEL_CH1);
  TIM_OC_InitStruct.OCMode = LL_TIM_OCMODE_PWM1;
  TIM_OC_InitStruct.OCState = LL_TIM_OCSTATE_DISABLE;
  TIM_OC_InitStruct.OCNState = LL_TIM_OCSTATE_DISABLE;
  TIM_OC_InitStruct.CompareValue = 0;
  TIM_OC_InitStruct.OCPolarity = LL_TIM_OCPOLARITY_HIGH;
  TIM_OC_InitStruct.OCNPolarity = LL_TIM_OCPOLARITY_HIGH;
  TIM_OC_InitStruct.OCIdleState = LL_TIM_OCIDLESTATE_LOW;
  TIM_OC_InitStruct.OCNIdleState = LL_TIM_OCIDLESTATE_LOW;
  LL_TIM_OC_Init(TIM1, LL_TIM_CHANNEL_CH1, &TIM_OC_InitStruct);
  LL_TIM_OC_DisableFast(TIM1, LL_TIM_CHANNEL_CH1);
  LL_TIM_SetTriggerOutput(TIM1, LL_TIM_TRGO_RESET);
  LL_TIM_DisableMasterSlaveMode(TIM1);
  TIM_BDTRInitStruct.OSSRState = LL_TIM_OSSR_DISABLE;
  TIM_BDTRInitStruct.OSSIState = LL_TIM_OSSI_DISABLE;
  TIM_BDTRInitStruct.LockLevel = LL_TIM_LOCKLEVEL_OFF;
  TIM_BDTRInitStruct.DeadTime = 0;
  TIM_BDTRInitStruct.BreakState = LL_TIM_BREAK_DISABLE;
  TIM_BDTRInitStruct.BreakPolarity = LL_TIM_BREAK_POLARITY_HIGH;
  TIM_BDTRInitStruct.AutomaticOutput = LL_TIM_AUTOMATICOUTPUT_ENABLE;
  LL_TIM_BDTR_Init(TIM1, &TIM_BDTRInitStruct);
  LL_AHB1_GRP1_EnableClock(LL_AHB1_GRP1_PERIPH_GPIOA);
  /**TIM1 GPIO Configuration
  PA8   ------> TIM1_CH1
  */
  GPIO_InitStruct.Pin = ID601_SERIAL_OUT_Pin;
  GPIO_InitStruct.Mode = LL_GPIO_MODE_ALTERNATE;
  GPIO_InitStruct.Speed = LL_GPIO_SPEED_FREQ_HIGH;
  GPIO_InitStruct.OutputType = LL_GPIO_OUTPUT_PUSHPULL;
  GPIO_InitStruct.Pull = LL_GPIO_PULL_NO;
  GPIO_InitStruct.Alternate = LL_GPIO_AF_1;
  LL_GPIO_Init(ID601_SERIAL_OUT_GPIO_Port, &GPIO_InitStruct);

}

static void MX_TIM2_Init(void)
{

  LL_TIM_InitTypeDef TIM_InitStruct = {0};

  LL_GPIO_InitTypeDef GPIO_InitStruct = {0};

  /* Peripheral clock enable */
  LL_APB1_GRP1_EnableClock(LL_APB1_GRP1_PERIPH_TIM2);

  LL_AHB1_GRP1_EnableClock(LL_AHB1_GRP1_PERIPH_GPIOB);
  /**TIM2 GPIO Configuration
  PB3   ------> TIM2_CH2
  */
  GPIO_InitStruct.Pin = ID601_SERIAL_IN_Pin;
  GPIO_InitStruct.Mode = LL_GPIO_MODE_ALTERNATE;
  GPIO_InitStruct.Speed = LL_GPIO_SPEED_FREQ_VERY_HIGH;
  GPIO_InitStruct.OutputType = LL_GPIO_OUTPUT_PUSHPULL;
  GPIO_InitStruct.Pull = LL_GPIO_PULL_NO;
  GPIO_InitStruct.Alternate = LL_GPIO_AF_1;
  LL_GPIO_Init(ID601_SERIAL_IN_GPIO_Port, &GPIO_InitStruct);

  /* TIM2 DMA Init */

  /* TIM2_CH2_CH4 Init */
  LL_DMA_SetChannelSelection(DMA1, LL_DMA_STREAM_6, LL_DMA_CHANNEL_3);

  LL_DMA_SetDataTransferDirection(DMA1, LL_DMA_STREAM_6, LL_DMA_DIRECTION_PERIPH_TO_MEMORY);

  LL_DMA_SetStreamPriorityLevel(DMA1, LL_DMA_STREAM_6, LL_DMA_PRIORITY_LOW);

  LL_DMA_SetMode(DMA1, LL_DMA_STREAM_6, LL_DMA_MODE_NORMAL);

  LL_DMA_SetPeriphIncMode(DMA1, LL_DMA_STREAM_6, LL_DMA_PERIPH_NOINCREMENT);

  LL_DMA_SetMemoryIncMode(DMA1, LL_DMA_STREAM_6, LL_DMA_MEMORY_INCREMENT);

  LL_DMA_SetPeriphSize(DMA1, LL_DMA_STREAM_6, LL_DMA_PDATAALIGN_HALFWORD);

  LL_DMA_SetMemorySize(DMA1, LL_DMA_STREAM_6, LL_DMA_MDATAALIGN_HALFWORD);

  LL_DMA_DisableFifoMode(DMA1, LL_DMA_STREAM_6);

  TIM_InitStruct.Prescaler = 0;
  TIM_InitStruct.CounterMode = LL_TIM_COUNTERMODE_UP;
  TIM_InitStruct.Autoreload = 4294967295;
  TIM_InitStruct.ClockDivision = LL_TIM_CLOCKDIVISION_DIV1;
  LL_TIM_Init(TIM2, &TIM_InitStruct);
  LL_TIM_DisableARRPreload(TIM2);
  LL_TIM_SetClockSource(TIM2, LL_TIM_CLOCKSOURCE_INTERNAL);
  LL_TIM_SetTriggerInput(TIM2, LL_TIM_TS_TI2FP2);
  LL_TIM_SetSlaveMode(TIM2, LL_TIM_SLAVEMODE_RESET);
  LL_TIM_CC_DisableChannel(TIM2, LL_TIM_CHANNEL_CH2);
  LL_TIM_IC_SetFilter(TIM2, LL_TIM_CHANNEL_CH2, LL_TIM_IC_FILTER_FDIV1);
  LL_TIM_IC_SetPolarity(TIM2, LL_TIM_CHANNEL_CH2, LL_TIM_IC_POLARITY_RISING);
  LL_TIM_DisableIT_TRIG(TIM2);
  LL_TIM_DisableDMAReq_TRIG(TIM2);
  LL_TIM_IC_SetActiveInput(TIM2, LL_TIM_CHANNEL_CH1, LL_TIM_ACTIVEINPUT_INDIRECTTI);
  LL_TIM_IC_SetPrescaler(TIM2, LL_TIM_CHANNEL_CH1, LL_TIM_ICPSC_DIV1);
  LL_TIM_IC_SetFilter(TIM2, LL_TIM_CHANNEL_CH1, LL_TIM_IC_FILTER_FDIV1);
  LL_TIM_IC_SetPolarity(TIM2, LL_TIM_CHANNEL_CH1, LL_TIM_IC_POLARITY_FALLING);
  LL_TIM_IC_SetActiveInput(TIM2, LL_TIM_CHANNEL_CH2, LL_TIM_ACTIVEINPUT_DIRECTTI);
  LL_TIM_IC_SetPrescaler(TIM2, LL_TIM_CHANNEL_CH2, LL_TIM_ICPSC_DIV1);
  LL_TIM_SetTriggerOutput(TIM2, LL_TIM_TRGO_RESET);
  LL_TIM_DisableMasterSlaveMode(TIM2);

}

static void MX_TIM3_Init(void)
{

  LL_TIM_InitTypeDef TIM_InitStruct = {0};
  LL_TIM_OC_InitTypeDef TIM_OC_InitStruct = {0};

  LL_GPIO_InitTypeDef GPIO_InitStruct = {0};

  /* Peripheral clock enable */
  LL_APB1_GRP1_EnableClock(LL_APB1_GRP1_PERIPH_TIM3);

  /* TIM3 interrupt Init */
  NVIC_SetPriority(TIM3_IRQn, NVIC_EncodePriority(NVIC_GetPriorityGrouping(),5, 0));
  NVIC_EnableIRQ(TIM3_IRQn);

  TIM_InitStruct.Prescaler = 1;
  TIM_InitStruct.CounterMode = LL_TIM_COUNTERMODE_UP;
  TIM_InitStruct.Autoreload = 65535;
  TIM_InitStruct.ClockDivision = LL_TIM_CLOCKDIVISION_DIV1;
  LL_TIM_Init(TIM3, &TIM_InitStruct);
  LL_TIM_DisableARRPreload(TIM3);
  LL_TIM_SetClockSource(TIM3, LL_TIM_CLOCKSOURCE_INTERNAL);
  LL_TIM_OC_EnablePreload(TIM3, LL_TIM_CHANNEL_CH1);
  TIM_OC_InitStruct.OCMode = LL_TIM_OCMODE_PWM1;
  TIM_OC_InitStruct.OCState = LL_TIM_OCSTATE_DISABLE;
  TIM_OC_InitStruct.OCNState = LL_TIM_OCSTATE_DISABLE;
  TIM_OC_InitStruct.CompareValue = 0;
  TIM_OC_InitStruct.OCPolarity = LL_TIM_OCPOLARITY_HIGH;
  LL_TIM_OC_Init(TIM3, LL_TIM_CHANNEL_CH1, &TIM_OC_InitStruct);
  LL_TIM_OC_DisableFast(TIM3, LL_TIM_CHANNEL_CH1);
  LL_TIM_SetTriggerOutput(TIM3, LL_TIM_TRGO_RESET);
  LL_TIM_DisableMasterSlaveMode(TIM3);
  LL_TIM_OC_DisablePreload(TIM3, LL_TIM_CHANNEL_CH1);
  LL_AHB1_GRP1_EnableClock(LL_AHB1_GRP1_PERIPH_GPIOC);
  /**TIM3 GPIO Configuration
  PC6   ------> TIM3_CH1
  */
  GPIO_InitStruct.Pin = ID601_SVSYNC_Pin;
  GPIO_InitStruct.Mode = LL_GPIO_MODE_ALTERNATE;
  GPIO_InitStruct.Speed = LL_GPIO_SPEED_FREQ_HIGH;
  GPIO_InitStruct.OutputType = LL_GPIO_OUTPUT_PUSHPULL;
  GPIO_InitStruct.Pull = LL_GPIO_PULL_NO;
  GPIO_InitStruct.Alternate = LL_GPIO_AF_2;
  LL_GPIO_Init(ID601_SVSYNC_GPIO_Port, &GPIO_InitStruct);

}

static void MX_TIM4_Init(void)
{

  LL_TIM_InitTypeDef TIM_InitStruct = {0};
  LL_TIM_OC_InitTypeDef TIM_OC_InitStruct = {0};

  LL_GPIO_InitTypeDef GPIO_InitStruct = {0};

  /* Peripheral clock enable */
  LL_APB1_GRP1_EnableClock(LL_APB1_GRP1_PERIPH_TIM4);

  TIM_InitStruct.Prescaler = 8;
  TIM_InitStruct.CounterMode = LL_TIM_COUNTERMODE_UP;
  TIM_InitStruct.Autoreload = 49999;
  TIM_InitStruct.ClockDivision = LL_TIM_CLOCKDIVISION_DIV1;
  LL_TIM_Init(TIM4, &TIM_InitStruct);
  LL_TIM_DisableARRPreload(TIM4);
  LL_TIM_SetClockSource(TIM4, LL_TIM_CLOCKSOURCE_INTERNAL);
  LL_TIM_OC_EnablePreload(TIM4, LL_TIM_CHANNEL_CH1);
  TIM_OC_InitStruct.OCMode = LL_TIM_OCMODE_PWM1;
  TIM_OC_InitStruct.OCState = LL_TIM_OCSTATE_DISABLE;
  TIM_OC_InitStruct.OCNState = LL_TIM_OCSTATE_DISABLE;
  TIM_OC_InitStruct.CompareValue = 0;
  TIM_OC_InitStruct.OCPolarity = LL_TIM_OCPOLARITY_HIGH;
  LL_TIM_OC_Init(TIM4, LL_TIM_CHANNEL_CH1, &TIM_OC_InitStruct);
  LL_TIM_OC_DisableFast(TIM4, LL_TIM_CHANNEL_CH1);
  LL_TIM_SetTriggerOutput(TIM4, LL_TIM_TRGO_RESET);
  LL_TIM_DisableMasterSlaveMode(TIM4);
  LL_AHB1_GRP1_EnableClock(LL_AHB1_GRP1_PERIPH_GPIOB);
  /**TIM4 GPIO Configuration
  PB6   ------> TIM4_CH1
  */
  GPIO_InitStruct.Pin = IC603_FLLSYNC_Pin;
  GPIO_InitStruct.Mode = LL_GPIO_MODE_ALTERNATE;
  GPIO_InitStruct.Speed = LL_GPIO_SPEED_FREQ_HIGH;
  GPIO_InitStruct.OutputType = LL_GPIO_OUTPUT_PUSHPULL;
  GPIO_InitStruct.Pull = LL_GPIO_PULL_NO;
  GPIO_InitStruct.Alternate = LL_GPIO_AF_2;
  LL_GPIO_Init(IC603_FLLSYNC_GPIO_Port, &GPIO_InitStruct);

}

static void MX_TIM5_Init(void)
{

  LL_TIM_InitTypeDef TIM_InitStruct = {0};

  LL_GPIO_InitTypeDef GPIO_InitStruct = {0};

  /* Peripheral clock enable */
  LL_APB1_GRP1_EnableClock(LL_APB1_GRP1_PERIPH_TIM5);

  LL_AHB1_GRP1_EnableClock(LL_AHB1_GRP1_PERIPH_GPIOA);
  /**TIM5 GPIO Configuration
  PA0-WKUP   ------> TIM5_CH1
  */
  GPIO_InitStruct.Pin = CNT_FREQ_IN_Pin;
  GPIO_InitStruct.Mode = LL_GPIO_MODE_ALTERNATE;
  GPIO_InitStruct.Speed = LL_GPIO_SPEED_FREQ_VERY_HIGH;
  GPIO_InitStruct.OutputType = LL_GPIO_OUTPUT_PUSHPULL;
  GPIO_InitStruct.Pull = LL_GPIO_PULL_NO;
  GPIO_InitStruct.Alternate = LL_GPIO_AF_2;
  LL_GPIO_Init(CNT_FREQ_IN_GPIO_Port, &GPIO_InitStruct);

  /* TIM5 DMA Init */

  /* TIM5_CH1 Init */
  LL_DMA_SetChannelSelection(DMA1, LL_DMA_STREAM_2, LL_DMA_CHANNEL_6);

  LL_DMA_SetDataTransferDirection(DMA1, LL_DMA_STREAM_2, LL_DMA_DIRECTION_PERIPH_TO_MEMORY);

  LL_DMA_SetStreamPriorityLevel(DMA1, LL_DMA_STREAM_2, LL_DMA_PRIORITY_LOW);

  LL_DMA_SetMode(DMA1, LL_DMA_STREAM_2, LL_DMA_MODE_NORMAL);

  LL_DMA_SetPeriphIncMode(DMA1, LL_DMA_STREAM_2, LL_DMA_PERIPH_NOINCREMENT);

  LL_DMA_SetMemoryIncMode(DMA1, LL_DMA_STREAM_2, LL_DMA_MEMORY_INCREMENT);

  LL_DMA_SetPeriphSize(DMA1, LL_DMA_STREAM_2, LL_DMA_PDATAALIGN_WORD);

  LL_DMA_SetMemorySize(DMA1, LL_DMA_STREAM_2, LL_DMA_MDATAALIGN_WORD);

  LL_DMA_DisableFifoMode(DMA1, LL_DMA_STREAM_2);

  TIM_InitStruct.Prescaler = 0;
  TIM_InitStruct.CounterMode = LL_TIM_COUNTERMODE_UP;
  TIM_InitStruct.Autoreload = 4294967295;
  TIM_InitStruct.ClockDivision = LL_TIM_CLOCKDIVISION_DIV1;
  LL_TIM_Init(TIM5, &TIM_InitStruct);
  LL_TIM_DisableARRPreload(TIM5);
  LL_TIM_SetClockSource(TIM5, LL_TIM_CLOCKSOURCE_INTERNAL);
  LL_TIM_SetTriggerOutput(TIM5, LL_TIM_TRGO_RESET);
  LL_TIM_DisableMasterSlaveMode(TIM5);
  LL_TIM_IC_SetActiveInput(TIM5, LL_TIM_CHANNEL_CH1, LL_TIM_ACTIVEINPUT_DIRECTTI);
  LL_TIM_IC_SetPrescaler(TIM5, LL_TIM_CHANNEL_CH1, LL_TIM_ICPSC_DIV1);
  LL_TIM_IC_SetFilter(TIM5, LL_TIM_CHANNEL_CH1, LL_TIM_IC_FILTER_FDIV1);
  LL_TIM_IC_SetPolarity(TIM5, LL_TIM_CHANNEL_CH1, LL_TIM_IC_POLARITY_RISING);

}

static void MX_TIM8_Init(void)
{

  LL_TIM_InitTypeDef TIM_InitStruct = {0};
  LL_TIM_OC_InitTypeDef TIM_OC_InitStruct = {0};
  LL_TIM_BDTR_InitTypeDef TIM_BDTRInitStruct = {0};

  LL_GPIO_InitTypeDef GPIO_InitStruct = {0};

  /* Peripheral clock enable */
  LL_APB2_GRP1_EnableClock(LL_APB2_GRP1_PERIPH_TIM8);

  /* TIM8 interrupt Init */
  NVIC_SetPriority(TIM8_BRK_TIM12_IRQn, NVIC_EncodePriority(NVIC_GetPriorityGrouping(),5, 0));
  NVIC_EnableIRQ(TIM8_BRK_TIM12_IRQn);
  NVIC_SetPriority(TIM8_UP_TIM13_IRQn, NVIC_EncodePriority(NVIC_GetPriorityGrouping(),6, 0));
  NVIC_EnableIRQ(TIM8_UP_TIM13_IRQn);
  NVIC_SetPriority(TIM8_TRG_COM_TIM14_IRQn, NVIC_EncodePriority(NVIC_GetPriorityGrouping(),4, 0));
  NVIC_EnableIRQ(TIM8_TRG_COM_TIM14_IRQn);

  TIM_InitStruct.Prescaler = 49;
  TIM_InitStruct.CounterMode = LL_TIM_COUNTERMODE_UP;
  TIM_InitStruct.Autoreload = 59999;
  TIM_InitStruct.ClockDivision = LL_TIM_CLOCKDIVISION_DIV1;
  TIM_InitStruct.RepetitionCounter = 0;
  LL_TIM_Init(TIM8, &TIM_InitStruct);
  LL_TIM_EnableARRPreload(TIM8);
  LL_TIM_SetClockSource(TIM8, LL_TIM_CLOCKSOURCE_INTERNAL);
  LL_TIM_OC_EnablePreload(TIM8, LL_TIM_CHANNEL_CH2);
  TIM_OC_InitStruct.OCMode = LL_TIM_OCMODE_PWM1;
  TIM_OC_InitStruct.OCState = LL_TIM_OCSTATE_DISABLE;
  TIM_OC_InitStruct.OCNState = LL_TIM_OCSTATE_DISABLE;
  TIM_OC_InitStruct.CompareValue = 0;
  TIM_OC_InitStruct.OCPolarity = LL_TIM_OCPOLARITY_HIGH;
  TIM_OC_InitStruct.OCNPolarity = LL_TIM_OCPOLARITY_HIGH;
  TIM_OC_InitStruct.OCIdleState = LL_TIM_OCIDLESTATE_LOW;
  TIM_OC_InitStruct.OCNIdleState = LL_TIM_OCIDLESTATE_LOW;
  LL_TIM_OC_Init(TIM8, LL_TIM_CHANNEL_CH2, &TIM_OC_InitStruct);
  LL_TIM_OC_DisableFast(TIM8, LL_TIM_CHANNEL_CH2);
  LL_TIM_SetTriggerOutput(TIM8, LL_TIM_TRGO_RESET);
  LL_TIM_EnableMasterSlaveMode(TIM8);
  TIM_BDTRInitStruct.OSSRState = LL_TIM_OSSR_DISABLE;
  TIM_BDTRInitStruct.OSSIState = LL_TIM_OSSI_DISABLE;
  TIM_BDTRInitStruct.LockLevel = LL_TIM_LOCKLEVEL_OFF;
  TIM_BDTRInitStruct.DeadTime = 0;
  TIM_BDTRInitStruct.BreakState = LL_TIM_BREAK_DISABLE;
  TIM_BDTRInitStruct.BreakPolarity = LL_TIM_BREAK_POLARITY_HIGH;
  TIM_BDTRInitStruct.AutomaticOutput = LL_TIM_AUTOMATICOUTPUT_ENABLE;
  LL_TIM_BDTR_Init(TIM8, &TIM_BDTRInitStruct);
  LL_AHB1_GRP1_EnableClock(LL_AHB1_GRP1_PERIPH_GPIOC);
  /**TIM8 GPIO Configuration
  PC7   ------> TIM8_CH2
  */
  GPIO_InitStruct.Pin = VSYNC_Pin;
  GPIO_InitStruct.Mode = LL_GPIO_MODE_ALTERNATE;
  GPIO_InitStruct.Speed = LL_GPIO_SPEED_FREQ_LOW;
  GPIO_InitStruct.OutputType = LL_GPIO_OUTPUT_PUSHPULL;
  GPIO_InitStruct.Pull = LL_GPIO_PULL_NO;
  GPIO_InitStruct.Alternate = LL_GPIO_AF_3;
  LL_GPIO_Init(VSYNC_GPIO_Port, &GPIO_InitStruct);

}

static void MX_TIM11_Init(void)
{

  LL_TIM_InitTypeDef TIM_InitStruct = {0};

  /* Peripheral clock enable */
  LL_APB2_GRP1_EnableClock(LL_APB2_GRP1_PERIPH_TIM11);

  /* TIM11 interrupt Init */
  NVIC_SetPriority(TIM1_TRG_COM_TIM11_IRQn, NVIC_EncodePriority(NVIC_GetPriorityGrouping(),6, 0));
  NVIC_EnableIRQ(TIM1_TRG_COM_TIM11_IRQn);

  TIM_InitStruct.Prescaler = 24;
  TIM_InitStruct.CounterMode = LL_TIM_COUNTERMODE_UP;
  TIM_InitStruct.Autoreload = 59999;
  TIM_InitStruct.ClockDivision = LL_TIM_CLOCKDIVISION_DIV1;
  LL_TIM_Init(TIM11, &TIM_InitStruct);
  LL_TIM_DisableARRPreload(TIM11);

}

static void MX_TIM13_Init(void)
{

  LL_TIM_InitTypeDef TIM_InitStruct = {0};

  /* Peripheral clock enable */
  LL_APB1_GRP1_EnableClock(LL_APB1_GRP1_PERIPH_TIM13);

  /* TIM13 interrupt Init */
  NVIC_SetPriority(TIM8_UP_TIM13_IRQn, NVIC_EncodePriority(NVIC_GetPriorityGrouping(),6, 0));
  NVIC_EnableIRQ(TIM8_UP_TIM13_IRQn);

  TIM_InitStruct.Prescaler = 89;
  TIM_InitStruct.CounterMode = LL_TIM_COUNTERMODE_UP;
  TIM_InitStruct.Autoreload = 65535;
  TIM_InitStruct.ClockDivision = LL_TIM_CLOCKDIVISION_DIV1;
  LL_TIM_Init(TIM13, &TIM_InitStruct);
  LL_TIM_DisableARRPreload(TIM13);

}

static void MX_USART2_UART_Init(void)
{

  LL_USART_InitTypeDef USART_InitStruct = {0};

  LL_GPIO_InitTypeDef GPIO_InitStruct = {0};

  /* Peripheral clock enable */
  LL_APB1_GRP1_EnableClock(LL_APB1_GRP1_PERIPH_USART2);

  LL_AHB1_GRP1_EnableClock(LL_AHB1_GRP1_PERIPH_GPIOA);
  /**USART2 GPIO Configuration
  PA2   ------> USART2_TX
  PA3   ------> USART2_RX
  */
  GPIO_InitStruct.Pin = USART_TX_Pin|USART_RX_Pin;
  GPIO_InitStruct.Mode = LL_GPIO_MODE_ALTERNATE;
  GPIO_InitStruct.Speed = LL_GPIO_SPEED_FREQ_VERY_HIGH;
  GPIO_InitStruct.OutputType = LL_GPIO_OUTPUT_PUSHPULL;
  GPIO_InitStruct.Pull = LL_GPIO_PULL_NO;
  GPIO_InitStruct.Alternate = LL_GPIO_AF_7;
  LL_GPIO_Init(GPIOA, &GPIO_InitStruct);

  /* USART2 interrupt Init */
  NVIC_SetPriority(USART2_IRQn, NVIC_EncodePriority(NVIC_GetPriorityGrouping(),5, 0));
  NVIC_EnableIRQ(USART2_IRQn);

  USART_InitStruct.BaudRate = 115200;
  USART_InitStruct.DataWidth = LL_USART_DATAWIDTH_8B;
  USART_InitStruct.StopBits = LL_USART_STOPBITS_1;
  USART_InitStruct.Parity = LL_USART_PARITY_NONE;
  USART_InitStruct.TransferDirection = LL_USART_DIRECTION_TX_RX;
  USART_InitStruct.HardwareFlowControl = LL_USART_HWCONTROL_NONE;
  USART_InitStruct.OverSampling = LL_USART_OVERSAMPLING_16;
  LL_USART_Init(USART2, &USART_InitStruct);
  LL_USART_ConfigAsyncMode(USART2);
  LL_USART_Enable(USART2);

}

static void MX_DMA_Init(void)
{

  /* Init with LL driver */
  /* DMA controller clock enable */
  LL_AHB1_GRP1_EnableClock(LL_AHB1_GRP1_PERIPH_DMA2);
  LL_AHB1_GRP1_EnableClock(LL_AHB1_GRP1_PERIPH_DMA1);

  /* DMA interrupt init */
  /* DMA1_Stream2_IRQn interrupt configuration */
  NVIC_SetPriority(DMA1_Stream2_IRQn, NVIC_EncodePriority(NVIC_GetPriorityGrouping(),5, 0));
  NVIC_EnableIRQ(DMA1_Stream2_IRQn);
  /* DMA1_Stream3_IRQn interrupt configuration */
  NVIC_SetPriority(DMA1_Stream3_IRQn, NVIC_EncodePriority(NVIC_GetPriorityGrouping(),5, 0));
  NVIC_EnableIRQ(DMA1_Stream3_IRQn);
  /* DMA1_Stream4_IRQn interrupt configuration */
  NVIC_SetPriority(DMA1_Stream4_IRQn, NVIC_EncodePriority(NVIC_GetPriorityGrouping(),5, 0));
  NVIC_EnableIRQ(DMA1_Stream4_IRQn);
  /* DMA1_Stream6_IRQn interrupt configuration */
  NVIC_SetPriority(DMA1_Stream6_IRQn, NVIC_EncodePriority(NVIC_GetPriorityGrouping(),5, 0));
  NVIC_EnableIRQ(DMA1_Stream6_IRQn);
  /* DMA2_Stream0_IRQn interrupt configuration */
  NVIC_SetPriority(DMA2_Stream0_IRQn, NVIC_EncodePriority(NVIC_GetPriorityGrouping(),5, 0));
  NVIC_EnableIRQ(DMA2_Stream0_IRQn);
  /* DMA2_Stream1_IRQn interrupt configuration */
  NVIC_SetPriority(DMA2_Stream1_IRQn, NVIC_EncodePriority(NVIC_GetPriorityGrouping(),5, 0));
  NVIC_EnableIRQ(DMA2_Stream1_IRQn);
  /* DMA2_Stream3_IRQn interrupt configuration */
  NVIC_SetPriority(DMA2_Stream3_IRQn, NVIC_EncodePriority(NVIC_GetPriorityGrouping(),5, 0));
  NVIC_EnableIRQ(DMA2_Stream3_IRQn);

}

static void MX_GPIO_Init(void)
{
  LL_EXTI_InitTypeDef EXTI_InitStruct = {0};
  LL_GPIO_InitTypeDef GPIO_InitStruct = {0};

  /* GPIO Ports Clock Enable */
  LL_AHB1_GRP1_EnableClock(LL_AHB1_GRP1_PERIPH_GPIOC);
  LL_AHB1_GRP1_EnableClock(LL_AHB1_GRP1_PERIPH_GPIOH);
  LL_AHB1_GRP1_EnableClock(LL_AHB1_GRP1_PERIPH_GPIOA);
  LL_AHB1_GRP1_EnableClock(LL_AHB1_GRP1_PERIPH_GPIOB);
  LL_AHB1_GRP1_EnableClock(LL_AHB1_GRP1_PERIPH_GPIOD);

  /**/
  LL_GPIO_ResetOutputPin(GPIOC, LTC_CURRENT_HIGH_Pin|BUFFER_OE_Pin|IC603_5V5_EN_Pin);

  /**/
  LL_GPIO_ResetOutputPin(GPIOA, LTC_CURRENT_LOW_Pin|LTC_CURRENT_MID_Pin|DEBUG1_Pin);

  /**/
  LL_GPIO_ResetOutputPin(DEBUG2_GPIO_Port, DEBUG2_Pin);

  /**/
  LL_GPIO_SetOutputPin(GPIOC, IC603_VCC_EN_Pin|ID601_CH_DEMUX1_Pin);

  /**/
  LL_GPIO_SetOutputPin(GPIOB, ID601_CH_DEMUX4_Pin|VLED_DCDC_EN_Pin|ID601_CH_DEMUX3_Pin|CNT_RST_Pin
                          |ID601_VCC_EN_MBD_Pin|IC603_CS_Pin);

  /**/
  LL_GPIO_SetOutputPin(GPIOA, ADC_CS1_Pin|ID601_CH_DEMUX2_Pin|ADC_CS2_Pin);

  /**/
  GPIO_InitStruct.Pin = B1_Pin|IC603_FB3_Pin|IC603_FB2_Pin;
  GPIO_InitStruct.Mode = LL_GPIO_MODE_INPUT;
  GPIO_InitStruct.Pull = LL_GPIO_PULL_NO;
  LL_GPIO_Init(GPIOC, &GPIO_InitStruct);

  /**/
  GPIO_InitStruct.Pin = LTC_CURRENT_HIGH_Pin|BUFFER_OE_Pin|IC603_VCC_EN_Pin|ID601_CH_DEMUX1_Pin
                          |IC603_5V5_EN_Pin;
  GPIO_InitStruct.Mode = LL_GPIO_MODE_OUTPUT;
  GPIO_InitStruct.Speed = LL_GPIO_SPEED_FREQ_LOW;
  GPIO_InitStruct.OutputType = LL_GPIO_OUTPUT_PUSHPULL;
  GPIO_InitStruct.Pull = LL_GPIO_PULL_NO;
  LL_GPIO_Init(GPIOC, &GPIO_InitStruct);

  /**/
  GPIO_InitStruct.Pin = LTC_CURRENT_LOW_Pin|LTC_CURRENT_MID_Pin|ADC_CS1_Pin|DEBUG1_Pin
                          |ID601_CH_DEMUX2_Pin|ADC_CS2_Pin;
  GPIO_InitStruct.Mode = LL_GPIO_MODE_OUTPUT;
  GPIO_InitStruct.Speed = LL_GPIO_SPEED_FREQ_LOW;
  GPIO_InitStruct.OutputType = LL_GPIO_OUTPUT_PUSHPULL;
  GPIO_InitStruct.Pull = LL_GPIO_PULL_NO;
  LL_GPIO_Init(GPIOA, &GPIO_InitStruct);

  /**/
  GPIO_InitStruct.Pin = ID601_CH_DEMUX4_Pin|VLED_DCDC_EN_Pin|ID601_CH_DEMUX3_Pin|CNT_RST_Pin
                          |DEBUG2_Pin|ID601_VCC_EN_MBD_Pin|IC603_CS_Pin;
  GPIO_InitStruct.Mode = LL_GPIO_MODE_OUTPUT;
  GPIO_InitStruct.Speed = LL_GPIO_SPEED_FREQ_LOW;
  GPIO_InitStruct.OutputType = LL_GPIO_OUTPUT_PUSHPULL;
  GPIO_InitStruct.Pull = LL_GPIO_PULL_NO;
  LL_GPIO_Init(GPIOB, &GPIO_InitStruct);

  /**/
  GPIO_InitStruct.Pin = IC603_MCLK_Pin;
  GPIO_InitStruct.Mode = LL_GPIO_MODE_ALTERNATE;
  GPIO_InitStruct.Speed = LL_GPIO_SPEED_FREQ_LOW;
  GPIO_InitStruct.OutputType = LL_GPIO_OUTPUT_PUSHPULL;
  GPIO_InitStruct.Pull = LL_GPIO_PULL_NO;
  GPIO_InitStruct.Alternate = LL_GPIO_AF_0;
  LL_GPIO_Init(IC603_MCLK_GPIO_Port, &GPIO_InitStruct);

  /**/
  GPIO_InitStruct.Pin = IC603_FB1_Pin;
  GPIO_InitStruct.Mode = LL_GPIO_MODE_INPUT;
  GPIO_InitStruct.Pull = LL_GPIO_PULL_NO;
  LL_GPIO_Init(IC603_FB1_GPIO_Port, &GPIO_InitStruct);

  /**/
  LL_SYSCFG_SetEXTISource(LL_SYSCFG_EXTI_PORTC, LL_SYSCFG_EXTI_LINE4);

  /**/
  LL_SYSCFG_SetEXTISource(LL_SYSCFG_EXTI_PORTB, LL_SYSCFG_EXTI_LINE13);

  /**/
  LL_SYSCFG_SetEXTISource(LL_SYSCFG_EXTI_PORTB, LL_SYSCFG_EXTI_LINE14);

  /**/
  LL_SYSCFG_SetEXTISource(LL_SYSCFG_EXTI_PORTA, LL_SYSCFG_EXTI_LINE10);

  /**/
  EXTI_InitStruct.Line_0_31 = LL_EXTI_LINE_4;
  EXTI_InitStruct.LineCommand = ENABLE;
  EXTI_InitStruct.Mode = LL_EXTI_MODE_IT;
  EXTI_InitStruct.Trigger = LL_EXTI_TRIGGER_FALLING;
  LL_EXTI_Init(&EXTI_InitStruct);

  /**/
  EXTI_InitStruct.Line_0_31 = LL_EXTI_LINE_13;
  EXTI_InitStruct.LineCommand = ENABLE;
  EXTI_InitStruct.Mode = LL_EXTI_MODE_IT;
  EXTI_InitStruct.Trigger = LL_EXTI_TRIGGER_FALLING;
  LL_EXTI_Init(&EXTI_InitStruct);

  /**/
  EXTI_InitStruct.Line_0_31 = LL_EXTI_LINE_14;
  EXTI_InitStruct.LineCommand = ENABLE;
  EXTI_InitStruct.Mode = LL_EXTI_MODE_IT;
  EXTI_InitStruct.Trigger = LL_EXTI_TRIGGER_FALLING;
  LL_EXTI_Init(&EXTI_InitStruct);

  /**/
  EXTI_InitStruct.Line_0_31 = LL_EXTI_LINE_10;
  EXTI_InitStruct.LineCommand = ENABLE;
  EXTI_InitStruct.Mode = LL_EXTI_MODE_IT;
  EXTI_InitStruct.Trigger = LL_EXTI_TRIGGER_FALLING;
  LL_EXTI_Init(&EXTI_InitStruct);

  /**/
  LL_GPIO_SetPinPull(ADC_DRDY1_GPIO_Port, ADC_DRDY1_Pin, LL_GPIO_PULL_UP);

  /**/
  LL_GPIO_SetPinPull(IC603_nINT_LD_GPIO_Port, IC603_nINT_LD_Pin, LL_GPIO_PULL_NO);

  /**/
  LL_GPIO_SetPinPull(ADC_DRDY2_GPIO_Port, ADC_DRDY2_Pin, LL_GPIO_PULL_UP);

  /**/
  LL_GPIO_SetPinPull(IC603_nINT_FAULT_GPIO_Port, IC603_nINT_FAULT_Pin, LL_GPIO_PULL_NO);

  /**/
  LL_GPIO_SetPinMode(ADC_DRDY1_GPIO_Port, ADC_DRDY1_Pin, LL_GPIO_MODE_INPUT);

  /**/
  LL_GPIO_SetPinMode(IC603_nINT_LD_GPIO_Port, IC603_nINT_LD_Pin, LL_GPIO_MODE_INPUT);

  /**/
  LL_GPIO_SetPinMode(ADC_DRDY2_GPIO_Port, ADC_DRDY2_Pin, LL_GPIO_MODE_INPUT);

  /**/
  LL_GPIO_SetPinMode(IC603_nINT_FAULT_GPIO_Port, IC603_nINT_FAULT_Pin, LL_GPIO_MODE_INPUT);

  /* EXTI interrupt init*/
  NVIC_SetPriority(EXTI4_IRQn, NVIC_EncodePriority(NVIC_GetPriorityGrouping(),5, 0));
  NVIC_EnableIRQ(EXTI4_IRQn);
  NVIC_SetPriority(EXTI15_10_IRQn, NVIC_EncodePriority(NVIC_GetPriorityGrouping(),5, 0));
  NVIC_EnableIRQ(EXTI15_10_IRQn);

}

void StartID601TestTask(void *argument)
{
  /* USER CODE BEGIN 5 */
    static thread_data_t td = { 0U };

  /* Infinite loop */
  for(;;)
  {
      uint32_t flags = osThreadFlagsWait(TEST_START_FLAG, osFlagsWaitAny, osWaitForever);

      if ((int32_t)flags < 0)
      {
          /* 플래그 대기 오류 처리 */
          continue;
      }

      drv_uart_printf(LOG_LV_INFO, "\r\n    [RTOS] Test Task Started");
      id601_test_start(&td);

      while (true == id601_test_process(&td))
      {
          if (td.tout > 0U)
          {
              osDelay(td.tout);
          }
      }
      drv_uart_printf(LOG_LV_INFO, "\r\n    [RTOS] Test Task Finished");
      drv_uart_printf(LOG_LV_INFO, "%s", CLI_PROMPT);
  }
  /* USER CODE END 5 */
}

void StartCLITask(void *argument)
{
  /* USER CODE BEGIN StartCLITask */
  /* Infinite loop */
  for(;;)
  {
    osDelay(10U);
    cli_process();
  }
  /* USER CODE END StartCLITask */
}

void StartID601TrimTask(void *argument)
{
  /* USER CODE BEGIN StartID601TrimTask */
    static thread_data_t td = { 0U };
  /* Infinite loop */
  for(;;)
  {
      uint32_t flags = osThreadFlagsWait(TRIM_START_FLAG, osFlagsWaitAny, osWaitForever);

      if ((int32_t)flags < 0)
      {
          /* 플래그 대기 오류 처리 */
          continue;
      }

      drv_uart_printf(LOG_LV_INFO, "\r\n    [RTOS] Trim Task Started");
      id601_trim_start(&td);

      while (true == id601_trim_process(&td))
      {
          if (td.tout > 0U)
          {
              osDelay(td.tout);
          }
      }
      drv_uart_printf(LOG_LV_INFO, "\r\n    [RTOS] Trim Task Finished");
      drv_uart_printf(LOG_LV_INFO, "%s", CLI_PROMPT);
  }
  /* USER CODE END StartID601TrimTask */
}

void StartVsyncTask(void *argument)
{
  /* USER CODE BEGIN StartVsyncTask */
    id601_dimming_init();
  /* Infinite loop */
  for(;;)
  {
      uint32_t flags = osThreadFlagsWait(VSYNC_DIMMING_FLAG, osFlagsWaitAny, osWaitForever);

      if ((int32_t)flags < 0)
      {
          /* 플래그 대기 오류 처리 */
          continue;
      }

      id601_vsync_dimming_task();
  }
  /* USER CODE END StartVsyncTask */
}

void StartBTNTask(void *argument)
{
  /* USER CODE BEGIN StartBTNTask */
  /* Infinite loop */
  for(;;)
  {
    drv_gpio_btn_task();
    osDelay(BTN_B1_DETECT_INTERVAL_MS);
  }
  /* USER CODE END StartBTNTask */
}

void HAL_TIM_PeriodElapsedCallback(TIM_HandleTypeDef *htim)
{
  if (htim->Instance == TIM14)
  {
    HAL_IncTick();
  }
}

void Error_Handler(void)
{
  __disable_irq();
  while (1)
  {
  }
}
